# ADuCM363 register map
Vendor: Analog Devices Inc.; Series: ADuCM36x; File version: 0.1
CPU: CM3 r2p1, little endian, no MPU, no FPU, 3 interrupt priority bits
Registers are 16-bit, read-write, no defined reset value unless marked. A register's access mark holds for its fields unless they carry their own. Offsets are from the block's base; [hi:lo] are bit positions.

## ADI_I2C — I2C
Base 0x40003000
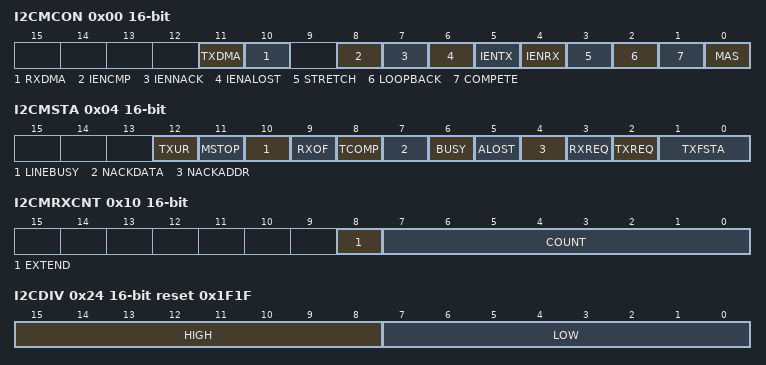
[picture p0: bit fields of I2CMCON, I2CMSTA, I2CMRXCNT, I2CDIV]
0x00 I2CMCON — Master Control Register
  [all] fields
    0=DIS; 1=EN
  [11] TXDMA — Enable master Tx DMA request
  [10] RXDMA — Enable master Rx DMA request
  [8] IENCMP — Transaction completed interrupt enable
  [7] IENNACK — ACK not received interrupt enable
  [6] IENALOST — Arbitration lost interrupt enable
  [5] IENTX — Transmit request interrupt enable
  [4] IENRX — Receive request interrupt enable
  [3] STRETCH — Stretch SCL
  [2] LOOPBACK — Internal loop back
  [1] COMPETE — Compete for ownership
  [0] MAS — Master Enable
0x04 I2CMSTA ro — Master Status Register
  [12] TXUR — Master Transmit FIFO underflow
    0=CLR; 1=SET
  [11] MSTOP — STOP driven by th eI2C master
    0=CLR; 1=SET
  [10] LINEBUSY — Line is busy
    0=CLR; 1=SET
  [9] RXOF — Receive FIFO overflow
    0=CLR; 1=SET
  [8] TCOMP — Transaction completed
    0=CLR; 1=SET
  [7] NACKDATA — Ack not received in response to data write
    0=CLR; 1=SET
  [6] BUSY — Master Busy
    0=CLR; 1=SET
  [5] ALOST — Arbitration lost
    0=CLR; 1=SET
  [4] NACKADDR — Ack not received in response to an address
    0=CLR; 1=SET
  [3] RXREQ — Receive request
    0=CLR; 1=SET
  [2] TXREQ — Transmit request
    0=CLR; 1=SET
  [1:0] TXFSTA — Transmit FIFO Status
    0=EMPTY; 1=ONEBYTE; 3=FULL
0x08 I2CMRX 8-bit ro — Master Receive Data
  [7:0] VALUE range 0x00000000..0x000000FF — Current Receive Value
0x0C I2CMTX 8-bit wo — Master Transmit Data
  [7:0] VALUE range 0x00000000..0x000000FF — Current Transmit Value
0x10 I2CMRXCNT — Master Receive Data Count
  [8] EXTEND — Extended Read
    0=DIS; 1=EN
  [7:0] COUNT range 0x00000000..0x000000FF — Receive count
0x14 I2CMCRXCNT ro — Master Current Receive Data Count
  [7:0] VALUE range 0x00000000..0x000000FF — Current Receive count
0x18 I2CADR0 8-bit — 1st Master Address Byte
  [7:0] VALUE range 0x00000000..0x000000FF — Address byte
0x1C I2CADR1 8-bit — 2nd Master Address Byte
  [7:0] VALUE range 0x00000000..0x000000FF — Address byte
0x24 I2CDIV reset 0x1F1F (reset mask 0x0) — Serial clock period divisor register
  [15:8] HIGH range 0x00000000..0x000000FF — High Time
  [7:0] LOW range 0x00000000..0x000000FF — Low Time
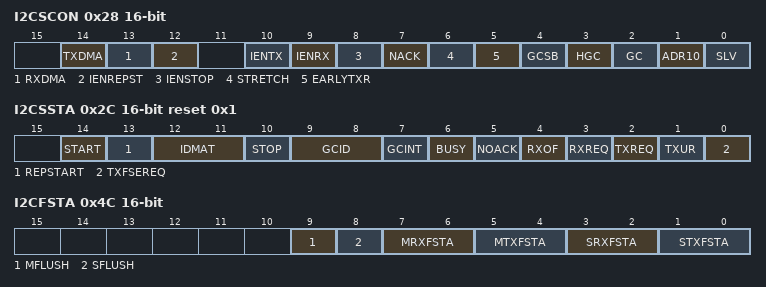
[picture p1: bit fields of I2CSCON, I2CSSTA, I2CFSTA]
0x28 I2CSCON — Slave Control Register
  [14] TXDMA — Enable slave Tx DMA request
    0=DIS; 1=EN
  [13] RXDMA — Enable slave Rx DMA request
    0=DIS; 1=EN
  [12] IENREPST — Repeated start interrupt enable
    0=DIS; 1=EN
  [10] IENTX — Transmit request interrupt enable
    0=DIS; 1=EN
  [9] IENRX — Receive request interrupt enable
    0=DIS; 1=EN
  [8] IENSTOP — Stop condition detected interrupt enable
    0=DIS; 1=EN
  [7] NACK — NACK next communication
    0=DIS; 1=EN
  [6] STRETCH — Stretch SCL
    0=DIS; 1=EN
  [5] EARLYTXR — Early transmit request mode
    0=DIS; 1=EN
  [4] GCSB — General call status bit clear
    1=CLR
  [3] HGC — Hardware general Call enable
    0=DIS; 1=EN
  [2] GC — General Call enable
    0=DIS; 1=EN
  [1] ADR10 — Enable 10 bit addressing
    0=DIS; 1=EN
  [0] SLV — Slave Enable
    0=DIS; 1=EN
0x2C I2CSSTA ro reset 0x1 (reset mask 0x0) — Slave I2C Status, Error and IRQ Register
  [all] fields
    0=CLR; 1=SET
  [14] START — Start and matching address
  [13] REPSTART — Repeated start and matching address
  [12:11] IDMAT — Device ID matched
  [10] STOP — Stop after start and matching address
  [9:8] GCID — General ID
  [7] GCINT — General call
  [6] BUSY — Slave busy
  [5] NOACK — Ack not generated by the slave
  [4] RXOF — Receive FIFO
  [3] RXREQ — Receive
  [2] TXREQ — Transmit
  [1] TXUR — Transmit FIFO underflow
  [0] TXFSEREQ — Tx FIFO status or early request
0x30 I2CSRX ro — Slave Receive Data Register
  [7:0] VALUE range 0x00000000..0x000000FF — Receive register
0x34 I2CSTX wo — Slave Transmit Data Register
  [7:0] VALUE range 0x00000000..0x000000FF — Transmit register
0x38 I2CALT — Hardware General Call ID
  [7:0] VALUE range 0x00000000..0x000000FF — Alt register
0x3C I2CID0 — 1st Slave Address Device ID
  [7:0] VALUE range 0x00000000..0x000000FF — Slave ID
0x40 I2CID1 — 2nd Slave Address Device ID
  [7:0] VALUE range 0x00000000..0x000000FF — Slave ID
0x44 I2CID2 — 3rd Slave Address Device ID
  [7:0] VALUE range 0x00000000..0x000000FF — Slave ID
0x48 I2CID3 — 4th Slave Address Device ID
  [7:0] VALUE range 0x00000000..0x000000FF — Slave ID
0x4C I2CFSTA — Master and Slave Rx/Tx FIFO Status Register
  [9] MFLUSH — Flush the master transmit FIFO
    0=DIS; 1=EN
  [8] SFLUSH — Flush the slave transmit FIFO
    0=DIS; 1=EN
  [7:6] MRXFSTA — Master receive FIFO Status
    0=EMPTY; 1=ONEBYTE; 2=TWOBYTES
  [5:4] MTXFSTA — Master Transmit FIFO Status
    0=EMPTY; 1=ONEBYTE; 2=TWOBYTES
  [3:2] SRXFSTA — Slave receive FIFO Status
    0=EMPTY; 1=ONEBYTE; 2=TWOBYTES
  [1:0] STXFSTA — Slave Transmit FIFO Status
    0=EMPTY; 1=ONEBYTE; 2=TWOBYTES
